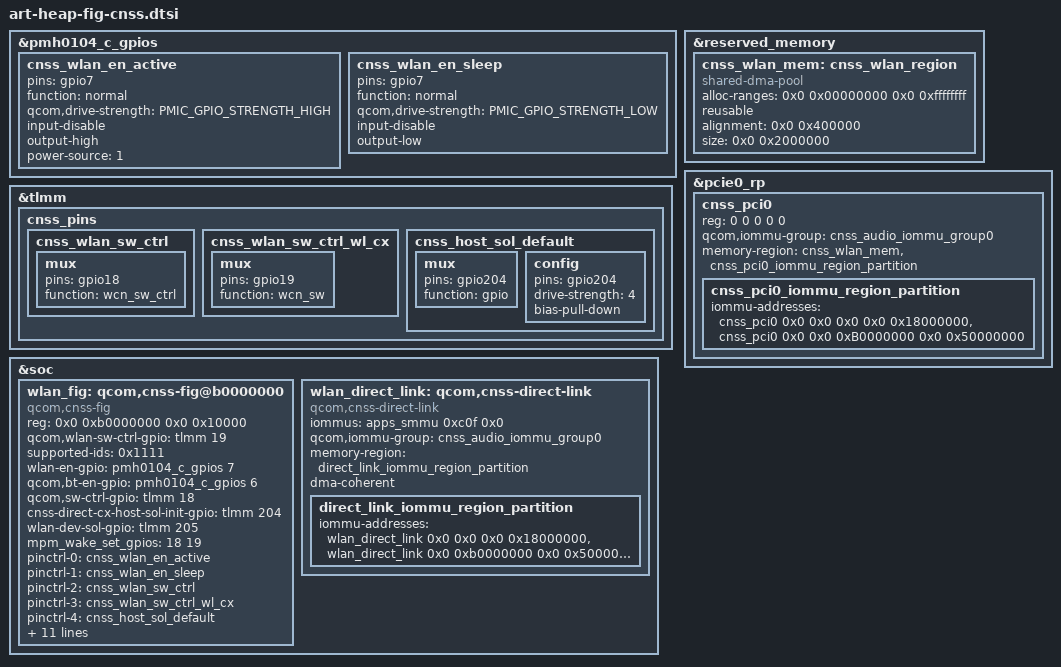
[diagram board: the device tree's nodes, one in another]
// SPDX-License-Identifier: BSD-3-Clause
/*
 * Copyright (c) Qualcomm Technologies, Inc. and/or its subsidiaries.
 */

#include <dt-bindings/interconnect/qcom,art.h>
#include <dt-bindings/pinctrl/qcom,pmic-gpio.h>

&pmh0104_c_gpios {
	cnss_wlan_en_active: cnss_wlan_en_active {
		pins = "gpio7";
		function = "normal";
		qcom,drive-strength = <PMIC_GPIO_STRENGTH_HIGH>;
		input-disable;
		output-high;
		power-source = <1>; /* 1.2 V*/
	};

	cnss_wlan_en_sleep: cnss_wlan_en_sleep {
		pins = "gpio7";
		function = "normal";
		qcom,drive-strength = <PMIC_GPIO_STRENGTH_LOW>;
		input-disable;
		output-low;
	};
};

&tlmm {
	cnss_pins {
		cnss_wlan_sw_ctrl: cnss_wlan_sw_ctrl {
			mux {
				pins = "gpio18";
				function = "wcn_sw_ctrl";
			};
		};

		cnss_wlan_sw_ctrl_wl_cx: cnss_wlan_sw_ctrl_wl_cx {
			mux {
				pins = "gpio19";
				function = "wcn_sw";
			};
		};

		cnss_host_sol_default: cnss_host_sol_default {
			mux {
				pins = "gpio204";
				function = "gpio";
			};

			config {
				pins = "gpio204";
				drive-strength = <4>;
				bias-pull-down;
			};
		};
	};
};

&reserved_memory {
	cnss_wlan_mem: cnss_wlan_region {
		compatible = "shared-dma-pool";
		alloc-ranges = <0x0 0x00000000 0x0 0xffffffff>;
		reusable;
		alignment = <0x0 0x400000>;
		size = <0x0 0x2000000>;
	};
};

&soc {
	wlan_fig: qcom,cnss-fig@b0000000 {
		compatible = "qcom,cnss-fig";
		reg = <0x0 0xb0000000 0x0 0x10000>;
		reg-names = "smmu_iova_ipa";
		qcom,wlan-sw-ctrl-gpio = <&tlmm 19 0>;

		supported-ids = <0x1111>;
		wlan-en-gpio = <&pmh0104_c_gpios 7 0>;
		qcom,bt-en-gpio = <&pmh0104_c_gpios 6 0>;
		qcom,sw-ctrl-gpio = <&tlmm 18 0>;
		cnss-direct-cx-host-sol-init-gpio = <&tlmm 204 0>;
		wlan-dev-sol-gpio = <&tlmm 205 0>;
		/* List of GPIOs to be setup for interrupt wakeup capable */
		mpm_wake_set_gpios = <18 19>;
		pinctrl-names = "wlan_en_active", "wlan_en_sleep", "sw_ctrl",
				"sw_ctrl_wl_cx", "sol_default";
		pinctrl-0 = <&cnss_wlan_en_active>;
		pinctrl-1 = <&cnss_wlan_en_sleep>;
		pinctrl-2 = <&cnss_wlan_sw_ctrl>;
		pinctrl-3 = <&cnss_wlan_sw_ctrl_wl_cx>;
		pinctrl-4 = <&cnss_host_sol_default>;
		qcom,wlan;
		qcom,wlan-rc-num = <0>;
		qcom,wlan-ramdump-dynamic = <0x600000>;
		cnss-enable-self-recovery;
		use-pm-domain;
		qcom,same-dt-multi-dev;
		/* For AOP communication, use direct QMP instead of mailbox */
		//qcom,qmp = <&aoss_qmp>;
		msix-match-addr = <0x3000>;
		platform-name-required;
		fig-direct-cx;
		cx-reg-name = "S3C0";

		//vdd-wlan-aon-supply = <&L2D>;
		//qcom,vdd-wlan-aon-config = <1800000 2000000 30000 0 1>;
		//vdd-wlan-io12-supply = <&L4G>;
		//qcom,vdd-wlan-io12-config = <1200000 1980000 30000 0 1>;
		//vdd-wlan-cx-supply = <&S3C>;
		//qcom,vdd-wlan-cx-config = <865000 2100000 0 0 1>;
		//vdd-wlan-dig-supply = <&S1J_E1>;
		//qcom,vdd-wlan-dig-config = <892000 1352000 0 0 1>;
		//vdd-wlan-rfa1-supply = <&S4C>;
		//qcom,vdd-wlan-rfa1-config = <1876000 2040000 0 0 1>;
		//vdd-wlan-rfa2-supply = <&S7G>;
		//qcom,vdd-wlan-rfa2-config = <1328000 1372000 0 0 1>;
		//vdd-wlan-ant-share-supply = <&L3K>;
		//qcom,vdd-wlan-ant-share-config = <1256000 2000000 25 0 1>;

		/* cpu mask used for wlan tx rx interrupt affinity
		 * <cpumask_for_rx_interrupts cpumask_for_tx_comp_interrupts>
		 */
		wlan-txrx-intr-cpumask = <0x3 0x30>;

		/* PMIC reg & regulator for XOCAL purpose

		nvmem-cells = <&xo_calib_data>;
		nvmem-cell-names = "xo_calib_reg";
		wcal-pbs-supply = <&WCAL_PBS>;*/
	};

	wlan_direct_link: qcom,cnss-direct-link {
		compatible = "qcom,cnss-direct-link";
		#address-cells = <2>;
		#size-cells = <2>;
		iommus = <&apps_smmu 0xc0f 0x0>;
		qcom,iommu-group = <&cnss_audio_iommu_group0>;
		memory-region = <&direct_link_iommu_region_partition>;
		dma-coherent;

		direct_link_iommu_region_partition: direct_link_iommu_region_partition {
			iommu-addresses = <&wlan_direct_link 0x0 0x0 0x0 0x18000000>,
				<&wlan_direct_link 0x0 0xb0000000 0x0 0x50000000>;
		};
	};
};

&pcie0_rp {
		#address-cells = <3>;
		#size-cells = <2>;

	cnss_pci0: cnss_pci0 {
		reg = <0 0 0 0 0>;
		qcom,iommu-group = <&cnss_audio_iommu_group0>;
		memory-region = <&cnss_wlan_mem &cnss_pci0_iommu_region_partition>;
		cnss_pci0_iommu_region_partition: cnss_pci0_iommu_region_partition {
			/* address-cells =3 size-cells=2 from art-pcie.dtsi */
			iommu-addresses = <&cnss_pci0 0x0 0x0 0x0 0x0 0x18000000>,
					  <&cnss_pci0 0x0 0x0 0xB0000000 0x0 0x50000000>;
		};
	};
};
